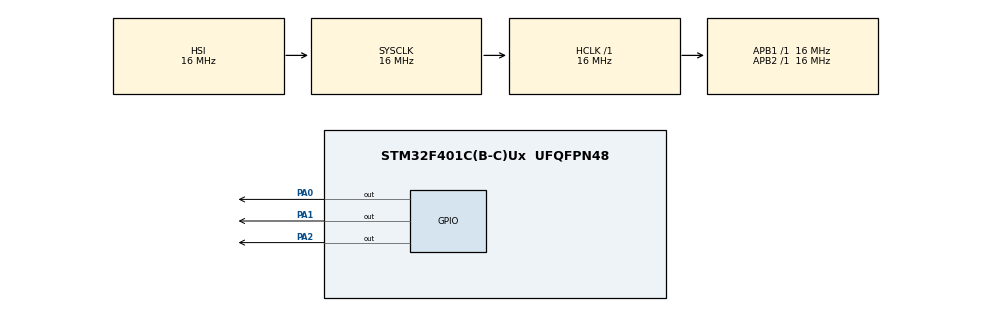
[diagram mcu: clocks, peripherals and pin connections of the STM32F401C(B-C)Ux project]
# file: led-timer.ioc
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Mcu.Family=STM32F4
Mcu.Name=STM32F401C(B-C)Ux
Mcu.Package=UFQFPN48
NVIC.PriorityGroup=NVIC_PRIORITYGROUP_4
NVIC.TIM2_IRQn=true\:0\:0\:false\:false\:true\:true\:true\:true
PA0-WKUP.Signal=GPIO_Output
PA1.Signal=GPIO_Output
PA13.Mode=Serial_Wire
PA13.Signal=SYS_JTMS-SWDIO
PA14.Mode=Serial_Wire
PA14.Signal=SYS_JTCK-SWCLK
PA2.Signal=GPIO_Output
ProjectManager.HeapSize=0x200
ProjectManager.StackSize=0x400
ProjectManager.TargetToolchain=STM32CubeIDE
RCC.AHBFreq_Value=16000000
RCC.APB1Freq_Value=16000000
RCC.APB2Freq_Value=16000000
RCC.CortexFreq_Value=16000000
RCC.HSE_VALUE=25000000
RCC.HSI_VALUE=16000000
RCC.LSE_VALUE=32768
RCC.SYSCLKFreq_VALUE=16000000
RCC.VCOOutputFreq_Value=192000000
TIM2.Period=99
TIM2.Prescaler=15999
VP_TIM2_VS_ClockSourceINT.Mode=Internal
board=custom

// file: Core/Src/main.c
/* USER CODE BEGIN Header */
/**
  ******************************************************************************
  * @file           : main.c
  * @brief          : Main program body
  ******************************************************************************
  * @attention
  *
  * Copyright (c) 2026 STMicroelectronics.
  * All rights reserved.
  *
  * This software is licensed under terms that can be found in the LICENSE file
  * in the root directory of this software component.
  * If no LICENSE file comes with this software, it is provided AS-IS.
  *
  ******************************************************************************
  */
/* USER CODE END Header */
#include "main.h"

/* USER CODE BEGIN Includes */
#include <stdbool.h>

/* USER CODE END Includes */

/* USER CODE BEGIN PTD */

typedef struct {
	GPIO_TypeDef *port;
	uint16_t pin;
	uint32_t counterMs;
	uint32_t toggleThresholdMs;
	volatile bool shouldToggle;
} BlinkingLedConfig;

/* USER CODE END PTD */

/* USER CODE BEGIN PD */

#define LED_COUNT (sizeof(ledConfigs) / sizeof(ledConfigs[0]))

/* USER CODE END PD */

TIM_HandleTypeDef htim2;

/* USER CODE BEGIN PV */

volatile BlinkingLedConfig ledConfigs[] = {
		{GPIOA, GPIO_PIN_0, 0, 2, false},
		{GPIOA, GPIO_PIN_1, 0, 5, false},
		{GPIOA, GPIO_PIN_2, 0, 10, false},
};

/* USER CODE END PV */

void SystemClock_Config(void);
static void MX_GPIO_Init(void);
static void MX_TIM2_Init(void);

/* USER CODE BEGIN 0 */

void HAL_TIM_PeriodElapsedCallback(TIM_HandleTypeDef *htim) {
	if (htim->Instance == TIM2) {
		for (int i = 0; i < LED_COUNT; i++) {
			volatile BlinkingLedConfig *conf = &ledConfigs[i];
			conf->counterMs++;
			if (conf->counterMs >= conf->toggleThresholdMs) {
				conf->shouldToggle = true;
				conf->counterMs = 0;
			}
		}
	}
}

/* USER CODE END 0 */

int main(void)
{

  /* MCU Configuration--------------------------------------------------------*/

  /* Reset of all peripherals, Initializes the Flash interface and the Systick. */
  HAL_Init();

  /* Configure the system clock */
  SystemClock_Config();

  /* Initialize all configured peripherals */
  MX_GPIO_Init();
  MX_TIM2_Init();
  /* USER CODE BEGIN 2 */

//  HAL_TIM_Base_Start_IT(&htim2);

  if (HAL_TIM_Base_Start_IT(&htim2) != HAL_OK)
  {
      Error_Handler();
  }

  /* USER CODE END 2 */

  /* Infinite loop */
  /* USER CODE BEGIN WHILE */
  while (1)
  {
	for (int i = 0; i < LED_COUNT; i++) {
		volatile BlinkingLedConfig *conf = &ledConfigs[i];
		if (conf->shouldToggle) {
			HAL_GPIO_TogglePin(conf->port, conf->pin);
			conf->shouldToggle = false;
		}
	}
//	  debugTimerCounter = __HAL_TIM_GET_COUNTER(&htim2);
//      HAL_GPIO_TogglePin(GPIOA, GPIO_PIN_0);
    /* USER CODE END WHILE */

  }
}

void SystemClock_Config(void)
{
  RCC_OscInitTypeDef RCC_OscInitStruct = {0};
  RCC_ClkInitTypeDef RCC_ClkInitStruct = {0};

  /** Configure the main internal regulator output voltage
  */
  __HAL_RCC_PWR_CLK_ENABLE();
  __HAL_PWR_VOLTAGESCALING_CONFIG(PWR_REGULATOR_VOLTAGE_SCALE2);

  /** Initializes the RCC Oscillators according to the specified parameters
  * in the RCC_OscInitTypeDef structure.
  */
  RCC_OscInitStruct.OscillatorType = RCC_OSCILLATORTYPE_HSI;
  RCC_OscInitStruct.HSIState = RCC_HSI_ON;
  RCC_OscInitStruct.HSICalibrationValue = RCC_HSICALIBRATION_DEFAULT;
  RCC_OscInitStruct.PLL.PLLState = RCC_PLL_NONE;
  if (HAL_RCC_OscConfig(&RCC_OscInitStruct) != HAL_OK)
  {
    Error_Handler();
  }

  /** Initializes the CPU, AHB and APB buses clocks
  */
  RCC_ClkInitStruct.ClockType = RCC_CLOCKTYPE_HCLK|RCC_CLOCKTYPE_SYSCLK
                              |RCC_CLOCKTYPE_PCLK1|RCC_CLOCKTYPE_PCLK2;
  RCC_ClkInitStruct.SYSCLKSource = RCC_SYSCLKSOURCE_HSI;
  RCC_ClkInitStruct.AHBCLKDivider = RCC_SYSCLK_DIV1;
  RCC_ClkInitStruct.APB1CLKDivider = RCC_HCLK_DIV1;
  RCC_ClkInitStruct.APB2CLKDivider = RCC_HCLK_DIV1;

  if (HAL_RCC_ClockConfig(&RCC_ClkInitStruct, FLASH_LATENCY_0) != HAL_OK)
  {
    Error_Handler();
  }
}

static void MX_TIM2_Init(void)
{

  TIM_ClockConfigTypeDef sClockSourceConfig = {0};
  TIM_MasterConfigTypeDef sMasterConfig = {0};

  htim2.Instance = TIM2;
  htim2.Init.Prescaler = 15999;
  htim2.Init.CounterMode = TIM_COUNTERMODE_UP;
  htim2.Init.Period = 99;
  htim2.Init.ClockDivision = TIM_CLOCKDIVISION_DIV1;
  htim2.Init.AutoReloadPreload = TIM_AUTORELOAD_PRELOAD_DISABLE;
  if (HAL_TIM_Base_Init(&htim2) != HAL_OK)
  {
    Error_Handler();
  }
  sClockSourceConfig.ClockSource = TIM_CLOCKSOURCE_INTERNAL;
  if (HAL_TIM_ConfigClockSource(&htim2, &sClockSourceConfig) != HAL_OK)
  {
    Error_Handler();
  }
  sMasterConfig.MasterOutputTrigger = TIM_TRGO_RESET;
  sMasterConfig.MasterSlaveMode = TIM_MASTERSLAVEMODE_DISABLE;
  if (HAL_TIMEx_MasterConfigSynchronization(&htim2, &sMasterConfig) != HAL_OK)
  {
    Error_Handler();
  }

}

static void MX_GPIO_Init(void)
{
  GPIO_InitTypeDef GPIO_InitStruct = {0};

  /* GPIO Ports Clock Enable */
  __HAL_RCC_GPIOA_CLK_ENABLE();

  /*Configure GPIO pin Output Level */
  HAL_GPIO_WritePin(GPIOA, GPIO_PIN_0|GPIO_PIN_1|GPIO_PIN_2, GPIO_PIN_RESET);

  /*Configure GPIO pins : PA0 PA1 PA2 */
  GPIO_InitStruct.Pin = GPIO_PIN_0|GPIO_PIN_1|GPIO_PIN_2;
  GPIO_InitStruct.Mode = GPIO_MODE_OUTPUT_PP;
  GPIO_InitStruct.Pull = GPIO_NOPULL;
  GPIO_InitStruct.Speed = GPIO_SPEED_FREQ_LOW;
  HAL_GPIO_Init(GPIOA, &GPIO_InitStruct);

}

void Error_Handler(void)
{
  __disable_irq();
  while (1)
  {
  }
}
